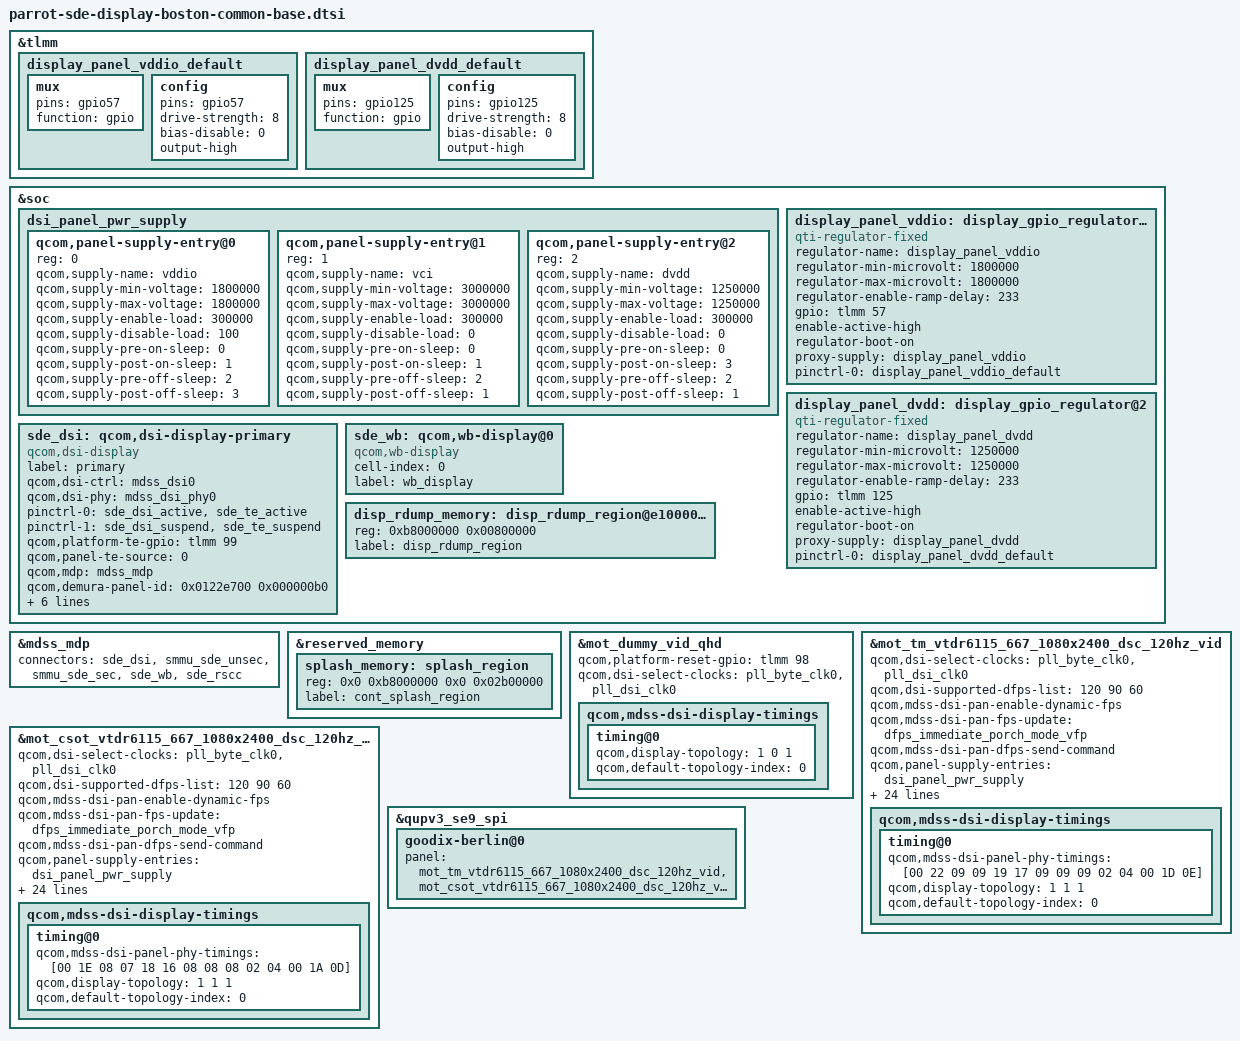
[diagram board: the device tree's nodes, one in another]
/*
   this is original from cape-sde-display-hiphi-common-base.dtsi
*/
#include <dt-bindings/clock/qcom,gcc-parrot.h>
#include <dt-bindings/clock/qcom,rpmh.h>
#include "parrot-sde-display-pinctrl.dtsi"
#include "dsi-panel-mot-dummy-qhd-video.dtsi"
#include <dt-bindings/clock/qcom,dispcc-parrot.h>
#include "dsi-panel-mot-tm-vtdr6115-667-1080x2400-dsc-120hz-vid.dtsi"
#include "dsi-panel-mot-csot-vtdr6115-667-1080x2400-dsc-120hz-vid.dtsi"

&tlmm {
	display_panel_vddio_default: display_panel_vddio_default {
		mux {
			pins = "gpio57";
			function = "gpio";
		};

		config {
			pins = "gpio57";
			drive-strength = <8>;
			bias-disable = <0>;
			output-high;
		};
	};

	display_panel_dvdd_default: display_panel_dvdd_default {
		mux {
			pins = "gpio125";
			function = "gpio";
		};

		config {
			pins = "gpio125";
			drive-strength = <8>;
			bias-disable = <0>;
			output-high;
		};
	};
};

&soc {
	dsi_panel_pwr_supply: dsi_panel_pwr_supply {
		#address-cells = <1>;
		#size-cells = <0>;

		qcom,panel-supply-entry@0 {
			reg = <0>;
			qcom,supply-name = "vddio";
			qcom,supply-min-voltage = <1800000>;
			qcom,supply-max-voltage = <1800000>;
			qcom,supply-enable-load = <300000>;
			qcom,supply-disable-load = <100>;
			qcom,supply-pre-on-sleep = <0>;
			qcom,supply-post-on-sleep = <1>;
			qcom,supply-pre-off-sleep = <2>;
			qcom,supply-post-off-sleep = <3>;
		};

		qcom,panel-supply-entry@1 {
			reg = <1>;
			qcom,supply-name = "vci";
			qcom,supply-min-voltage = <3000000>;
			qcom,supply-max-voltage = <3000000>;
			qcom,supply-enable-load = <300000>;
			qcom,supply-disable-load = <0>;
			qcom,supply-pre-on-sleep = <0>;
			qcom,supply-post-on-sleep = <1>;
			qcom,supply-pre-off-sleep = <2>;
			qcom,supply-post-off-sleep = <1>;
		};

		qcom,panel-supply-entry@2 {
			reg = <2>;
			qcom,supply-name = "dvdd";
			qcom,supply-min-voltage = <1250000>;
			qcom,supply-max-voltage = <1250000>;
			qcom,supply-enable-load = <300000>;
			qcom,supply-disable-load = <0>;
			qcom,supply-pre-on-sleep = <0>;
			qcom,supply-post-on-sleep = <3>;
			qcom,supply-pre-off-sleep = <2>;
			qcom,supply-post-off-sleep = <1>;
		};
	};

	/delete-node/ display_gpio_regulator@1;
	/delete-node/ display_gpio_regulator@2;
	/delete-node/ display_gpio_regulator@3;

	display_panel_vddio: display_gpio_regulator@1 {
		compatible = "qti-regulator-fixed";
		regulator-name = "display_panel_vddio";
		regulator-min-microvolt = <1800000>;
		regulator-max-microvolt = <1800000>;
		regulator-enable-ramp-delay = <233>;
		gpio = <&tlmm 57 0>;
		enable-active-high;
		regulator-boot-on;
		proxy-supply = <&display_panel_vddio>;
		pinctrl-names = "default";
		pinctrl-0 = <&display_panel_vddio_default>;
	};

	display_panel_dvdd: display_gpio_regulator@2 {
		compatible = "qti-regulator-fixed";
		regulator-name = "display_panel_dvdd";
		regulator-min-microvolt = <1250000>;
		regulator-max-microvolt = <1250000>;
		regulator-enable-ramp-delay = <233>;
		gpio = <&tlmm 125 0>;
		enable-active-high;
		regulator-boot-on;
		proxy-supply = <&display_panel_dvdd>;
		pinctrl-names = "default";
		pinctrl-0 = <&display_panel_dvdd_default>;
	};

	sde_dsi: qcom,dsi-display-primary {
		compatible = "qcom,dsi-display";
		label = "primary";

		qcom,dsi-ctrl = <&mdss_dsi0>;
		qcom,dsi-phy = <&mdss_dsi_phy0>;

		pinctrl-names = "panel_active", "panel_suspend";
		pinctrl-0 = <&sde_dsi_active &sde_te_active>;
		pinctrl-1 = <&sde_dsi_suspend &sde_te_suspend>;

		qcom,platform-te-gpio = <&tlmm 99 0>;
		qcom,panel-te-source = <0>;

		qcom,mdp = <&mdss_mdp>;
		qcom,demura-panel-id = <0x0122e700 0x000000b0>;
	};
};

&soc {
	sde_wb: qcom,wb-display@0 {
		compatible = "qcom,wb-display";
		cell-index = <0>;
		label = "wb_display";
	};

	disp_rdump_memory: disp_rdump_region@e1000000 {
		reg = <0xb8000000 0x00800000>;
		label = "disp_rdump_region";
	};
};

&sde_dsi {
	clocks = <&mdss_dsi_phy0 0>,
			<&mdss_dsi_phy0 1>,
			 /*
			  * Currently the dsi clock handles are under the dsi
			  * controller DT node. As soon as the controller probe
			  * finishes, the dispcc sync state can get called before
			  * the dsi_display probe potentially disturbing the clock
			  * votes for cont_splash use case. Hence we are no longer
			  * protected by the component model in this case against the
			  * disp cc sync state getting triggered after the dsi_ctrl
			  * probe. To protect against this incorrect sync state trigger
			  * add this dummy MDP clk vote handle to the dsi_display
			  * DT node. Since the dsi_display driver does not parse
			  * MDP clock nodes, no actual vote shall be added and this
			  * change is done just to satisfy sync state requirements.
			  */
			 <&dispcc DISP_CC_MDSS_MDP_CLK>;
	clock-names = "pll_byte_clk0", "pll_dsi_clk0",
			"mdp_core_clk";
};

&mdss_mdp {
	connectors = <&sde_dsi &smmu_sde_unsec &smmu_sde_sec &sde_wb &sde_rscc>;
};

&reserved_memory {
	splash_memory: splash_region {
		reg = <0x0 0xb8000000 0x0 0x02b00000>;
		label = "cont_splash_region";
	};
};

&sde_dsi {
	/delete-property/ vddio-supply;
	/delete-property/ vci-supply;
	/delete-property/ lab-supply;
	/delete-property/ ibb-supply;
	/delete-property/ extvdd-supply;
        vddio-supply = <&display_panel_vddio>;
	vci-supply = <&L4E>;
	dvdd-supply = <&display_panel_dvdd>;

	qcom,dsi-default-panel = <&mot_dummy_vid_qhd>;
};

&mot_dummy_vid_qhd {
	qcom,platform-reset-gpio = <&tlmm 98 0>;

	qcom,dsi-select-clocks = "pll_byte_clk0", "pll_dsi_clk0";
	qcom,mdss-dsi-display-timings {
		timing@0 {
			qcom,display-topology = <1 0 1>;
			qcom,default-topology-index = <0>;
		};
	};
};

&mot_tm_vtdr6115_667_1080x2400_dsc_120hz_vid {
	qcom,dsi-select-clocks = "pll_byte_clk0", "pll_dsi_clk0";

	qcom,dsi-supported-dfps-list = <120 90 60>;
	qcom,mdss-dsi-pan-enable-dynamic-fps;
	qcom,mdss-dsi-pan-fps-update = "dfps_immediate_porch_mode_vfp";
	qcom,mdss-dsi-pan-dfps-send-command;

	qcom,panel-supply-entries = <&dsi_panel_pwr_supply>;
	qcom,mdss-dsi-no-panel-on-read-support;
	qcom,mdss-dsi-bl-pmic-control-type = "bl_ctrl_dcs";
	qcom,mdss-dsi-bl-min-level = <1>;
	qcom,mdss-dsi-bl-max-level = <4095>;
	qcom,mdss-dsi-bl-default-level = <1757>;
	qcom,mdss-brightness-max-level = <4095>;
	qcom,platform-reset-gpio = <&tlmm 98 0>;
	qcom,platform-te-gpio = <&tlmm 99 0>;
	qcom,bl-dsc-cmd-state = "dsi_hs_mode";
	qcom,mdss-dsi-bl-inverted-dbv;

	qcom,esd-check-enabled;
	qcom,mdss-dsi-panel-status-check-mode = "reg_read";
	qcom,mdss-dsi-panel-status-command = [06 01 00 01 00 00 01 66];
	qcom,mdss-dsi-panel-status-command-state = "dsi_lp_mode";
	qcom,mdss-dsi-panel-status-value = <0 0 0>;
	qcom,mdss-dsi-panel-status-read-length = <3>;

	qcom,cellid-read-enabled;
	qcom,mdss-dsi-panel-cellid-read-length = <23>;
	qcom,mdss-dsi-panel-cellid-command = [06 01 00 01 00 00 01 5A];

	qcom,mdss-dsi-display-timings {
		timing@0 {
			qcom,mdss-dsi-panel-phy-timings = [00 22 09 09 19 17 09
				09 09 02 04 00 1D 0E];
			qcom,display-topology = <1 1 1>;
			qcom,default-topology-index = <0>;
		};
	};
};

&mot_csot_vtdr6115_667_1080x2400_dsc_120hz_vid {
	qcom,dsi-select-clocks = "pll_byte_clk0", "pll_dsi_clk0";

	qcom,dsi-supported-dfps-list = <120 90 60>;
	qcom,mdss-dsi-pan-enable-dynamic-fps;
	qcom,mdss-dsi-pan-fps-update = "dfps_immediate_porch_mode_vfp";
	qcom,mdss-dsi-pan-dfps-send-command;

	qcom,panel-supply-entries = <&dsi_panel_pwr_supply>;
	qcom,mdss-dsi-no-panel-on-read-support;
	qcom,mdss-dsi-bl-pmic-control-type = "bl_ctrl_dcs";
	qcom,mdss-dsi-bl-min-level = <1>;
	qcom,mdss-dsi-bl-max-level = <4095>;
	qcom,mdss-dsi-bl-default-level = <1757>;
	qcom,mdss-brightness-max-level = <4095>;
	qcom,platform-reset-gpio = <&tlmm 98 0>;
	qcom,platform-te-gpio = <&tlmm 99 0>;
	qcom,bl-dsc-cmd-state = "dsi_hs_mode";
	qcom,mdss-dsi-bl-inverted-dbv;

	qcom,esd-check-enabled;
	qcom,mdss-dsi-panel-status-check-mode = "reg_read";
	qcom,mdss-dsi-panel-status-command = [06 01 00 01 00 00 01 66];
	qcom,mdss-dsi-panel-status-command-state = "dsi_lp_mode";
	qcom,mdss-dsi-panel-status-value = <0 0 0>;
	qcom,mdss-dsi-panel-status-read-length = <3>;

	qcom,cellid-read-enabled;
	qcom,mdss-dsi-panel-cellid-read-length = <23>;
	qcom,mdss-dsi-panel-cellid-command = [06 01 00 01 00 00 01 C8];

	qcom,mdss-dsi-display-timings {
		timing@0 {
			qcom,mdss-dsi-panel-phy-timings = [00 1E 08 07 18 16 08
				08 08 02 04 00 1A 0D];
			qcom,display-topology = <1 1 1>;
			qcom,default-topology-index = <0>;
		};
	};
};

&qupv3_se9_spi {
	goodix-berlin@0 {
		panel = <&mot_tm_vtdr6115_667_1080x2400_dsc_120hz_vid
			&mot_csot_vtdr6115_667_1080x2400_dsc_120hz_vid>;
	};
};
